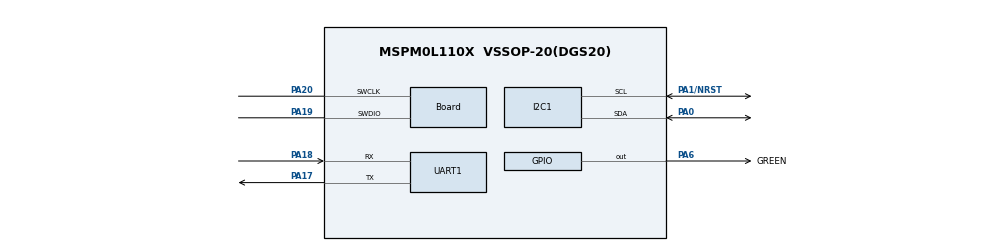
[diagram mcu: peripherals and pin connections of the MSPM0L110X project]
/**
 * @cliArgs --device "MSPM0L110X" --part "Default" --package "VSSOP-20(DGS20)" --product "mspm0_sdk@2.08.00.03"
 * @versions {"tool":"1.25.0+4268"}
 */

/**
 * Import the modules used in this configuration.
 */
const Board  = scripting.addModule("/ti/driverlib/Board");
const GPIO   = scripting.addModule("/ti/driverlib/GPIO", {}, false);
const GPIO1  = GPIO.addInstance();
const I2C    = scripting.addModule("/ti/driverlib/I2C", {}, false);
const I2C1   = I2C.addInstance();
const SYSCTL = scripting.addModule("/ti/driverlib/SYSCTL");
const UART   = scripting.addModule("/ti/driverlib/UART", {}, false);
const UART1  = UART.addInstance();

/**
 * Write custom configuration values to the imported modules.
 */
Board.configureUnused             = true;
Board.peripheral.$assign          = "DEBUGSS";
Board.peripheral.swclkPin.$assign = "PA20";
Board.peripheral.swdioPin.$assign = "PA19";

GPIO1.$name                         = "GPIO_LEDS";
GPIO1.port                          = "PORTA";
GPIO1.associatedPins.create(2);
GPIO1.associatedPins[0].$name       = "GREEN";
GPIO1.associatedPins[0].assignedPin = "6";
GPIO1.associatedPins[0].pin.$assign = "PA6";
GPIO1.associatedPins[1].$name       = "RED";
GPIO1.associatedPins[1].assignedPin = "11";

I2C1.$name                             = "I2C";
I2C1.basicEnableController             = true;
I2C1.basicControllerBusSpeed           = 400000;
I2C1.advAnalogGlitchFilter             = "DISABLED";
I2C1.advControllerTXFIFOTRIG           = "BYTES_1";
I2C1.peripheral.$assign                = "I2C0";
I2C1.peripheral.sdaPin.$assign         = "PA0";
I2C1.peripheral.sclPin.$assign         = "PA1/NRST";
I2C1.sdaPinConfig.$name                = "ti_driverlib_gpio_GPIOPinGeneric0";
I2C1.sdaPinConfig.hideOutputInversion  = scripting.forceWrite(false);
I2C1.sdaPinConfig.onlyInternalResistor = scripting.forceWrite(false);
I2C1.sdaPinConfig.passedPeripheralType = scripting.forceWrite("Digital");
I2C1.sclPinConfig.$name                = "ti_driverlib_gpio_GPIOPinGeneric1";
I2C1.sclPinConfig.hideOutputInversion  = scripting.forceWrite(false);
I2C1.sclPinConfig.onlyInternalResistor = scripting.forceWrite(false);
I2C1.sclPinConfig.passedPeripheralType = scripting.forceWrite("Digital");

SYSCTL.clockTreeEn    = true;
SYSCTL.disableNRSTPin = true;

UART1.$name                        = "UART_0";
UART1.enableFIFO                   = true;
UART1.targetBaudRate               = 115200;
UART1.peripheral.$assign           = "UART0";
UART1.peripheral.rxPin.$assign     = "PA18";
UART1.peripheral.txPin.$assign     = "PA17";
UART1.txPinConfig.$name            = "ti_driverlib_gpio_GPIOPinGeneric2";
UART1.rxPinConfig.$name            = "ti_driverlib_gpio_GPIOPinGeneric3";
UART1.rxPinConfig.enableConfig     = true;
UART1.rxPinConfig.internalResistor = "PULL_UP";

const ProjectConfig              = scripting.addModule("/ti/project_config/ProjectConfig", {}, false);
ProjectConfig.migrationCondition = true;

/**
 * Pinmux solution for unlocked pins/peripherals. This ensures that minor changes to the automatic solver in a future
 * version of the tool will not impact the pinmux you originally saw.  These lines can be completely deleted in order to
 * re-solve from scratch.
 */
GPIO1.associatedPins[1].pin.$suggestSolution = "PA11";
